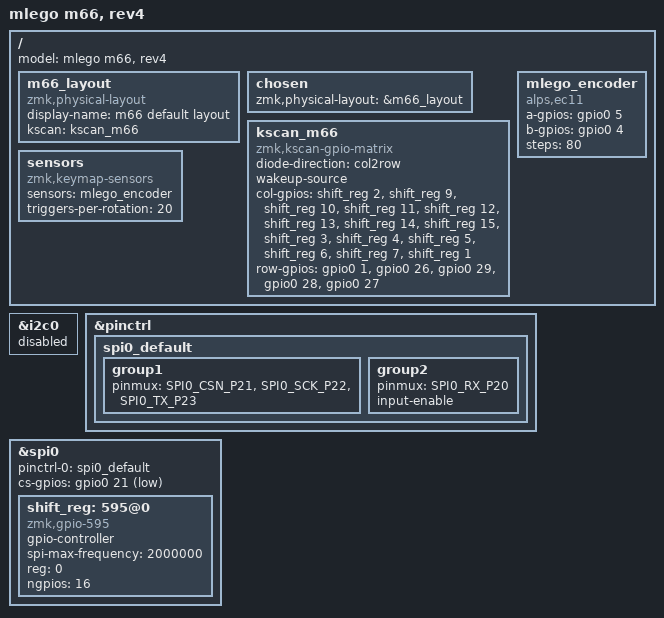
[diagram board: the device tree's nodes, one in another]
/*
 * Copyright (c) 2022-2024 alin m elena
 * SPDX-License-Identifier: MIT
 */
#include <dt-bindings/pinctrl/rpi-pico-rp2040-pinctrl.h>
#include "mlego_m66_rev4_layout.dtsi"

/ {
   model = "mlego m66, rev4";
    m66_layout: m66_layout {
        compatible = "zmk,physical-layout";
        display-name = "m66 default layout";
        kscan = <&kscan_m66>;
   };

   chosen {
     zmk,physical-layout = &m66_layout;
/*
     zephyr,console = &cdc_acm_uart;
*/
   };


   kscan_m66: kscan_m66 {
     compatible = "zmk,kscan-gpio-matrix";
     diode-direction = "col2row";
     wakeup-source;
     col-gpios =   <&shift_reg 2  (GPIO_ACTIVE_HIGH)>
                 , <&shift_reg 9  (GPIO_ACTIVE_HIGH)>
                 , <&shift_reg 10 (GPIO_ACTIVE_HIGH)>
                 , <&shift_reg 11 (GPIO_ACTIVE_HIGH)>
                 , <&shift_reg 12 (GPIO_ACTIVE_HIGH)>
                 , <&shift_reg 13 (GPIO_ACTIVE_HIGH)>
                 , <&shift_reg 14 (GPIO_ACTIVE_HIGH)>
                 , <&shift_reg 15 (GPIO_ACTIVE_HIGH)>
                 , <&shift_reg 3  (GPIO_ACTIVE_HIGH)>
                 , <&shift_reg 4  (GPIO_ACTIVE_HIGH)>
                 , <&shift_reg 5  (GPIO_ACTIVE_HIGH)>
                 , <&shift_reg 6  (GPIO_ACTIVE_HIGH)>
                 , <&shift_reg 7  (GPIO_ACTIVE_HIGH)>
                 , <&shift_reg 1  (GPIO_ACTIVE_HIGH)>
                 ;
     row-gpios =   <&gpio0 1 (GPIO_ACTIVE_HIGH | GPIO_PULL_DOWN)>
                 , <&gpio0 26 (GPIO_ACTIVE_HIGH | GPIO_PULL_DOWN)>
                 , <&gpio0 29 (GPIO_ACTIVE_HIGH | GPIO_PULL_DOWN)>
                 , <&gpio0 28 (GPIO_ACTIVE_HIGH | GPIO_PULL_DOWN)>
                 , <&gpio0 27 (GPIO_ACTIVE_HIGH | GPIO_PULL_DOWN)>
                 ;
   };

   mlego_encoder: mlego_encoder {
     compatible = "alps,ec11";
     a-gpios = <&gpio0 5 (GPIO_ACTIVE_HIGH )>;
     b-gpios = <&gpio0 4 (GPIO_ACTIVE_HIGH )>;
     steps = <80>;
   };

   sensors {
     compatible = "zmk,keymap-sensors";
     sensors = <&mlego_encoder>;
     triggers-per-rotation = <20>;
   };
};

&mlego_encoder { 
  status = "okay"; 
};

&i2c0 {
    status = "disabled";
};

&pinctrl {
  spi0_default: spi0_default {
                        group1 {
                                  pinmux = <SPI0_CSN_P21>, <SPI0_SCK_P22>, <SPI0_TX_P23>;
                        };
                        group2 {
                                pinmux = <SPI0_RX_P20>;
                                input-enable;
                        };
                };
};

board_spi: &spi0 {
  status = "okay";
  pinctrl-0 = < &spi0_default >;
  pinctrl-names = "default";
  cs-gpios = <&gpio0 21 GPIO_ACTIVE_LOW> ;
  shift_reg: 595@0 {
    compatible = "zmk,gpio-595";
    status = "okay";
    gpio-controller;
    spi-max-frequency = <2000000>;
    #gpio-cells = <2>;
    reg = <0>;
    ngpios = <16>;
  };
};
/*
&usbd {
    status = "okay";
    cdc_acm_uart: cdc_acm_uart {
        compatible = "zephyr,cdc-acm-uart";
    };
};
*/
